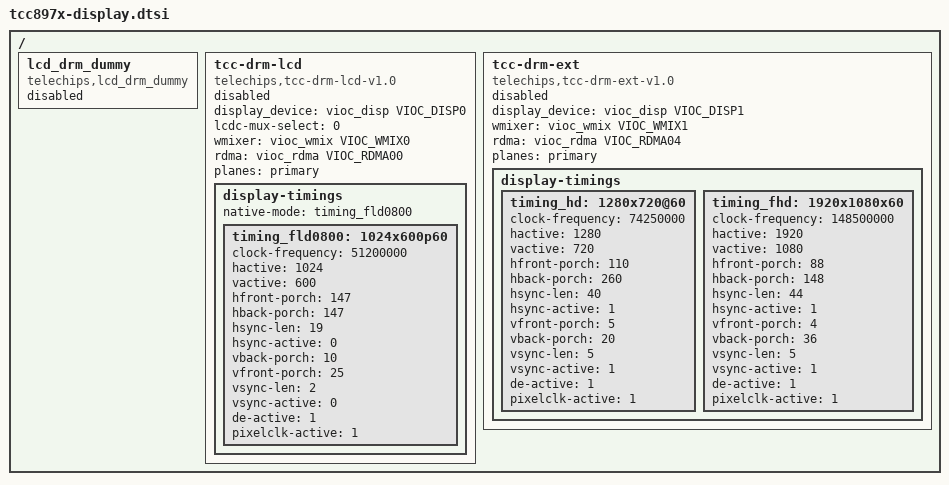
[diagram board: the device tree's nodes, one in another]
// SPDX-License-Identifier: (GPL-2.0-or-later OR MIT)
/*
 * Copyright (C) Telechips Inc.
* Device tree for Telechips TCC897x
 */
/ {
	/* Describe here after remove this statement if you have something to be override. */
	lcd_drm_dummy {
		compatible = "telechips,lcd_drm_dummy";
		status = "disabled";
	};

	tcc-drm-lcd {
		#address-cells = <1>;
		#size-cells = <0>;
		compatible = "telechips,tcc-drm-lcd-v1.0";
		display_device = <&vioc_disp VIOC_DISP0>;
		lcdc-mux-select = <0>;
		wmixer = <&vioc_wmix VIOC_WMIX0>;
		rdma = <&vioc_rdma VIOC_RDMA00>;
		planes = "primary";
		status = "disabled";

		display-timings {
			native-mode = <&timing_fld0800>;
			timing_fld0800: 1024x600p60 {
				clock-frequency = <51200000>;
				hactive = <1024>;
				vactive = <600>;
				hfront-porch = <147>;
				hback-porch = <147>;
				hsync-len = <19>;
				hsync-active = <0>;
				vback-porch = <10>;
				vfront-porch = <25>;
				vsync-len = <2>;
				vsync-active = <0>;
				de-active = <1>;
				pixelclk-active = <1>;
			};
		};
	};

	tcc-drm-ext {
		#address-cells = <1>;
		#size-cells = <0>;
		compatible = "telechips,tcc-drm-ext-v1.0";
		display_device = <&vioc_disp VIOC_DISP1>;
		wmixer = <&vioc_wmix VIOC_WMIX1>;
		rdma = <&vioc_rdma VIOC_RDMA04>;
		planes = "primary";
		status = "disabled";
		display-timings {
			timing_hd: 1280x720@60 {
				clock-frequency = <74250000>;
				hactive = <1280>;
				vactive = <720>;
				hfront-porch = <110>;
				hback-porch = <260>;
				hsync-len = <40>;
				hsync-active = <1>;
				vfront-porch = <5>;
				vback-porch = <20>;
				vsync-len = <5>;
				vsync-active = <1>;
				de-active = <1>;
				pixelclk-active = <1>;
			};
			timing_fhd: 1920x1080x60 {
				clock-frequency = <148500000>;
				hactive = <1920>;
				vactive = <1080>;
				hfront-porch = <88>;
				hback-porch = <148>;
				hsync-len = <44>;
				hsync-active = <1>;
				vfront-porch = <4>;
				vback-porch = <36>;
				vsync-len = <5>;
				vsync-active = <1>;
				de-active = <1>;
				pixelclk-active = <1>;
			};
		};

	};
};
